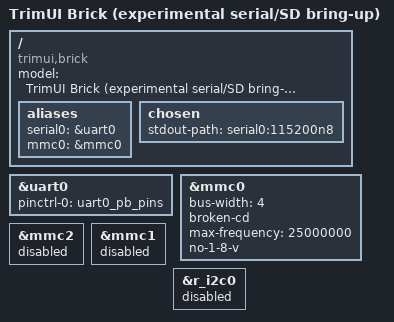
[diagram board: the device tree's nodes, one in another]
// SPDX-License-Identifier: (GPL-2.0+ OR MIT)
/*
 * Experimental serial + removable-SD bring-up only. NOT device verified.
 * Board wiring evidence: Plastron 414735de1c10c950e99defff0f4acf6567f13375,
 * board/brick/u-boot/patches/0004-trimui-brick-board.patch.
 * SoC definitions: upstream Linux v7.3 sun50i-a100.dtsi.
 *
 * Memory size/address MUST be populated by the validated bootloader's DRAM
 * fixup; deliberately not inferred from advertised RAM. Supply an initramfs.
 * PMIC/regulator bindings omitted until rail wiring is verified. This relies
 * on bootloader-established rails. No GPU/display/input support claimed.
 */
/dts-v1/;
#include "sun50i-a100.dtsi"
/ {
	model = "TrimUI Brick (experimental serial/SD bring-up)";
	compatible = "trimui,brick", "allwinner,sun50i-a100";
	aliases {
		serial0 = &uart0;
		mmc0 = &mmc0;
	};
	chosen {
		stdout-path = "serial0:115200n8";
	};
};
&uart0 {
	pinctrl-names = "default";
	pinctrl-0 = <&uart0_pb_pins>;
	status = "okay";
};
&mmc0 {
	bus-width = <4>;
	broken-cd;
	/* Conservative SD default-speed bring-up; no UHS voltage switching. */
	max-frequency = <25000000>;
	no-1-8-v;
	status = "okay";
};
/* Internal storage must remain unavailable in this development tree. */
&mmc2 { status = "disabled"; };
/* Unverified board peripherals remain unavailable. */
&mmc1 { status = "disabled"; };
&r_i2c0 { status = "disabled"; };
